# RockChip_RK3588 register map
Vendor: RockChip Electronics Co., Ltd.; Series: RK3588; File version: 0.1
Registers are 32-bit, read-write, no defined reset value unless marked. A register's access mark holds for its fields unless they carry their own. Offsets are from the block's base; [hi:lo] are bit positions; {n}, {i} and the like mark numbered series; 'fields as' and 'values as' point back to an identical list; <NAME> marks a mode.

## CRU_DSU
Base 0xFD818000
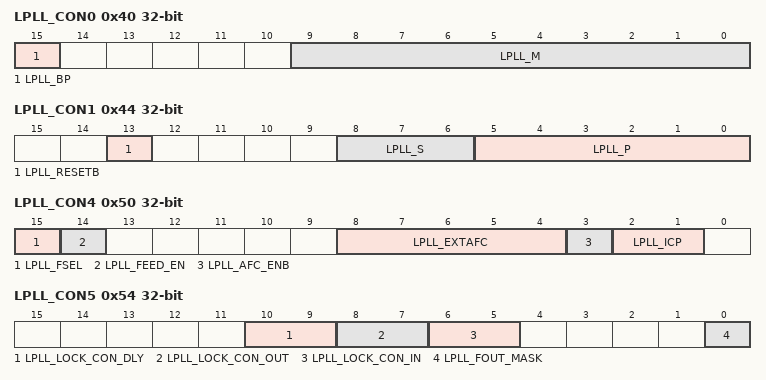
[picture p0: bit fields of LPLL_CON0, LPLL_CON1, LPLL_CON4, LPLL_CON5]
0x40 LPLL_CON0 — LPLL configuration register 0
  [15] LPLL_BP — BYPASS: Bypass mode control signal.
    1=BYPASS (bypass mode is enabled. (FOUT = FIN).); 0=NORMAL (PLL operates normally.)
  [9:0] LPLL_M — M: Division value of the 10-bit programmable main-divider. PLL has to be reset if M value is changed. 64 <= pll_m <= 1023
0x44 LPLL_CON1 — LPLL configuration register 1
  [13] LPLL_RESETB — RESETB: Power down control signal.
    0=NORMAL (RESETB=0 from 1, PLL starts its normal operation after lock time.); 1=POWER_DOWN (RESETB=1, power down mode is enabled and all digital blocks are reset.)
  [8:6] LPLL_S — Division value of the 3-bit programmable scaler. 0 <= pll_s <= 6
  [5:0] LPLL_P — P: Division value of the 6-bit programmable pre-divider. PLL has to be reset if P value is changed. 1 <= pll_p <= 63
0x50 LPLL_CON4 — LPLL configuration register 4
  [15] LPLL_FSEL — FSEL: Monitoring pin.
    0=FREF (FEED_OUT = FREF.); 1=FEED (FEED_OUT = FEED.)
  [14] LPLL_FEED_EN — FEED_EN: Monitoring pin.
    0=DISABLED (FEED_OUT is disabled.); 1=ENABLED (FEED_OUT is enabled.)
  [8:4] LPLL_EXTAFC — EXTAFC: Monitoring pin. If pll_afc_enb=1, AFC is disabled and VCO is calibrated manually by pll_extafc[4:0] for the test of VCO range.
  [3] LPLL_AFC_ENB — AFC_ENB: Monitoring pin.
    0=ENABLED (AFC is enabled and VCO is calibrated automatically.); 1=DISABLED (AFC is disabled and VCO is calibrated manually by pll_extafc[4:0] for the test of VCO range.)
  [2:1] LPLL_ICP — Charge-pump current control signal.
0x54 LPLL_CON5 — LPLL configuration register 5
  [10:9] LPLL_LOCK_CON_DLY — LOCK_CON_DLY: Lock detector setting of the detection resolution.
  [8:7] LPLL_LOCK_CON_OUT — LOCK_CON_OUT: Lock detector setting of the output margin.
  [6:5] LPLL_LOCK_CON_IN — LOCK_CON_IN: Lock detector setting of the input margin.
  [0] LPLL_FOUT_MASK — FOUT_MASK: Scaler's re-initialization time control pin.
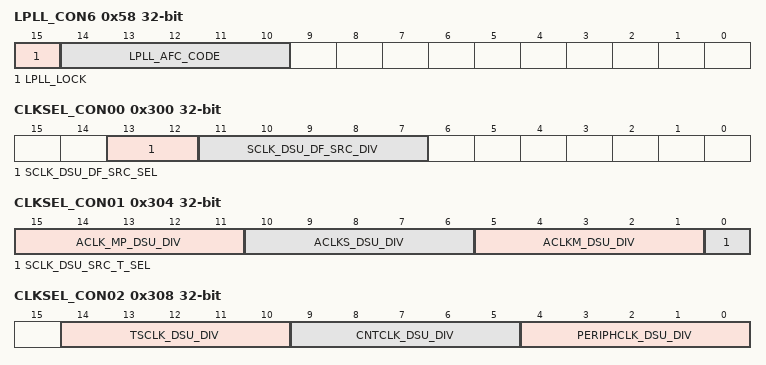
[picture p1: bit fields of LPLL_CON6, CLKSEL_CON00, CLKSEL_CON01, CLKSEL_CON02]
0x58 LPLL_CON6 — LPLL configuration register 6
  [15] LPLL_LOCK — LOCK: PLL lock flag.
    0=UNLOCKED (PLL is unlocked.); 1=LOCKED (PLL is locked.)
  [14:10] LPLL_AFC_CODE — AFC_CODE: Monitoring pin. Output code of AFC(5 bits).
0x280 MODE_CON00 — Internal PLL mode select register 0
  [1:0] CLK_LPLL_MODE — clk_lpll_mux clock mux.
    0=XIN_OSC0_FUNC; 1=CLK_LPLL; 2=CLK_DEEPSLOW
0x300 CLKSEL_CON00 — Internal clock select and division register 0
  [13:12] SCLK_DSU_DF_SRC_SEL — sclk_dsu_df_src clock mux.
    0=CLK_B0PLL_MUX; 1=CLK_B1PLL_MUX; 2=CLK_LPLL_MUX; 3=CLK_GPLL_MUX
  [11:7] SCLK_DSU_DF_SRC_DIV — Divide sclk_dsu_df_src by (div_con + 1).
0x304 CLKSEL_CON01 — Internal clock select and division register 1
  [15:11] ACLK_MP_DSU_DIV — Divide aclk_mp_dsu by (div_con + 1).
  [10:6] ACLKS_DSU_DIV — Divide aclks_dsu by (div_con + 1).
  [5:1] ACLKM_DSU_DIV — Divide aclkm_dsu by (div_con + 1).
  [0] SCLK_DSU_SRC_T_SEL — sclk_dsu_src_t clock mux.
    0=SCLK_DSU_SRC; 1=CLK_DSU_PVTPLL_T
0x308 CLKSEL_CON02 — Internal clock select and division register 2
  [14:10] TSCLK_DSU_DIV — Divide tsclk_dsu by (div_con + 1).
  [9:5] CNTCLK_DSU_DIV — Divide cntclk_dsu by (div_con + 1).
  [4:0] PERIPHCLK_DSU_DIV — Divide periphclk_dsu by (div_con + 1).
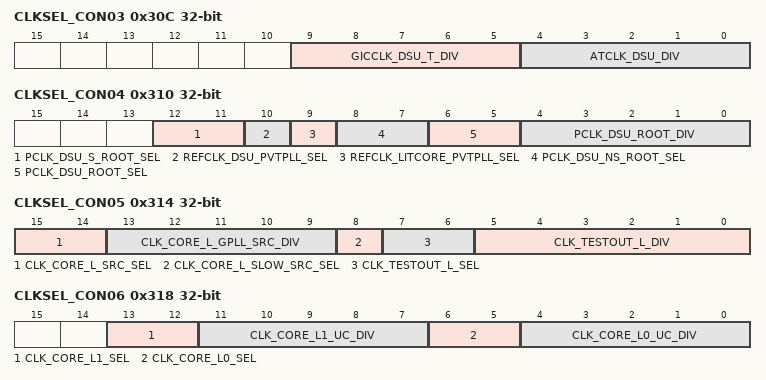
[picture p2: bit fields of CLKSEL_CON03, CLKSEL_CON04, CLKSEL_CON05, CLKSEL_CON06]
0x30C CLKSEL_CON03 — Internal clock select and division register 3
  [9:5] GICCLK_DSU_T_DIV — Divide gicclk_dsu_t by (div_con + 1).
  [4:0] ATCLK_DSU_DIV — Divide atclk_dsu by (div_con + 1).
0x310 CLKSEL_CON04 — Internal clock select and division register 4
  [12:11] PCLK_DSU_S_ROOT_SEL — pclk_dsu_s_root clock mux.
    0=CLK_MATRIX_100M_SRC; 1=CLK_MATRIX_50M_SRC; 2=XIN_OSC0_FUNC
  [10] REFCLK_DSU_PVTPLL_SEL — refclk_dsu_pvtpll clock mux.
    0=SCLK_DSU_SRC; 1=XIN_OSC0_FUNC
  [9] REFCLK_LITCORE_PVTPLL_SEL — refclk_litcore_pvtpll clock mux.
    0=CLK_CORE_L; 1=XIN_OSC0_FUNC
  [8:7] PCLK_DSU_NS_ROOT_SEL — pclk_dsu_ns_root clock mux.
    0=CLK_MATRIX_100M_SRC; 1=CLK_MATRIX_50M_SRC; 2=XIN_OSC0_FUNC
  [6:5] PCLK_DSU_ROOT_SEL — pclk_dsu_root clock mux.
    values as CLKSEL_CON00.SCLK_DSU_DF_SRC_SEL
  [4:0] PCLK_DSU_ROOT_DIV — Divide pclk_dsu_root by (div_con + 1).
0x314 CLKSEL_CON05 — Internal clock select and division register 5
  [15:14] CLK_CORE_L_SRC_SEL — clk_core_l_src clock mux.
    0=CLK_CORE_L_SLOW_SRC; 1=CLK_CORE_L_GPLL_SRC; 2=CLK_LPLL
  [13:9] CLK_CORE_L_GPLL_SRC_DIV — Divide clk_core_l_gpll_src by (div_con + 1).
  [8] CLK_CORE_L_SLOW_SRC_SEL — clk_core_l_slow_src clock mux.
    0=XIN_OSC0_FUNC; 1=CLK_DEEPSLOW
  [7:6] CLK_TESTOUT_L_SEL — clk_testout_l clock mux.
    0=CLK_LPLL; 1=CLK_CORE_L_PVTPLL; 2=SCLK_DSU_SRC; 3=CLK_DSU_PVTPLL
  [5:0] CLK_TESTOUT_L_DIV — Divide clk_testout_l by (div_con + 1).
0x318 CLKSEL_CON06 — Internal clock select and division register 6
  [13:12] CLK_CORE_L1_SEL — clk_core_l1 clock mux.
    0=CLK_CORE_L1_UC; 1=CLK_CORE_L1_CLEAN; 2=CLK_CORE_L_PVTPLL_T
  [11:7] CLK_CORE_L1_UC_DIV — Divide clk_core_l1_uc by (div_con + 1).
  [6:5] CLK_CORE_L0_SEL — clk_core_l0 clock mux.
    0=CLK_CORE_L0_UC; 1=CLK_CORE_L0_CLEAN; 2=CLK_CORE_L_PVTPLL_T
  [4:0] CLK_CORE_L0_UC_DIV — Divide clk_core_l0_uc by (div_con + 1).
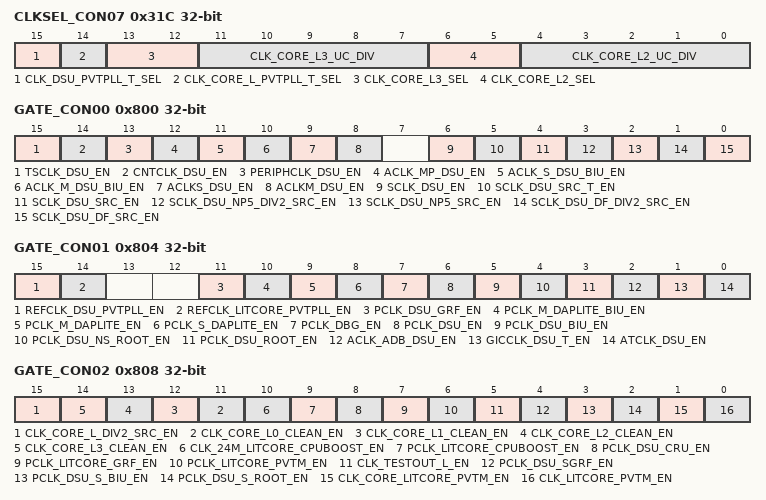
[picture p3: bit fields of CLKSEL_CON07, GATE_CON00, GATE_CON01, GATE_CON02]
0x31C CLKSEL_CON07 — Internal clock select and division register 7
  [15] CLK_DSU_PVTPLL_T_SEL — clk_dsu_pvtpll_t clock mux.
    0=CLK_DEEPSLOW; 1=CLK_DSU_PVTPLL
  [14] CLK_CORE_L_PVTPLL_T_SEL — clk_core_l_pvtpll_t clock mux.
    0=CLK_DEEPSLOW; 1=CLK_CORE_L_PVTPLL
  [13:12] CLK_CORE_L3_SEL — clk_core_l3 clock mux.
    0=CLK_CORE_L3_UC; 1=CLK_CORE_L3_CLEAN; 2=CLK_CORE_L_PVTPLL_T
  [11:7] CLK_CORE_L3_UC_DIV — Divide clk_core_l3_uc by (div_con + 1).
  [6:5] CLK_CORE_L2_SEL — clk_core_l2 clock mux.
    0=CLK_CORE_L2_UC; 1=CLK_CORE_L2_CLEAN; 2=CLK_CORE_L_PVTPLL_T
  [4:0] CLK_CORE_L2_UC_DIV — Divide clk_core_l2_uc by (div_con + 1).
0x800 GATE_CON00 — Internal clock gate and division register 0
  [all] fields
    0=ENABLE; 1=DISABLE
  [15] TSCLK_DSU_EN — tsclk_dsu clock gating control.
  [14] CNTCLK_DSU_EN — cntclk_dsu clock gating control.
  [13] PERIPHCLK_DSU_EN — periphclk_dsu clock gating control.
  [12] ACLK_MP_DSU_EN — aclk_mp_dsu clock gating control.
  [11] ACLK_S_DSU_BIU_EN — aclk_s_dsu_biu clock gating control.
  [10] ACLK_M_DSU_BIU_EN — aclk_m_dsu_biu clock gating control.
  [9] ACLKS_DSU_EN — aclks_dsu clock gating control.
  [8] ACLKM_DSU_EN — aclkm_dsu clock gating control.
  [6] SCLK_DSU_EN — sclk_dsu clock gating control.
  [5] SCLK_DSU_SRC_T_EN — sclk_dsu_src_t clock gating control.
  [4] SCLK_DSU_SRC_EN — sclk_dsu_src clock gating control.
  [3] SCLK_DSU_NP5_DIV2_SRC_EN — sclk_dsu_np5_div2_src clock gating control.
  [2] SCLK_DSU_NP5_SRC_EN — sclk_dsu_np5_src clock gating control.
  [1] SCLK_DSU_DF_DIV2_SRC_EN — sclk_dsu_df_div2_src clock gating control.
  [0] SCLK_DSU_DF_SRC_EN — sclk_dsu_df_src clock gating control.
0x804 GATE_CON01 — Internal clock gate and division register 1
  [all] fields
    0=ENABLE; 1=DISABLE
  [15] REFCLK_DSU_PVTPLL_EN — refclk_dsu_pvtpll clock gating control.
  [14] REFCLK_LITCORE_PVTPLL_EN — refclk_litcore_pvtpll clock gating control.
  [11] PCLK_DSU_GRF_EN — pclk_dsu_grf clock gating control.
  [10] PCLK_M_DAPLITE_BIU_EN — pclk_m_daplite_biu clock gating control.
  [9] PCLK_M_DAPLITE_EN — pclk_m_daplite clock gating control.
  [8] PCLK_S_DAPLITE_EN — pclk_s_daplite clock gating control.
  [7] PCLK_DBG_EN — pclk_dbg clock gating control.
  [6] PCLK_DSU_EN — pclk_dsu clock gating control.
  [5] PCLK_DSU_BIU_EN — pclk_dsu_biu clock gating control.
  [4] PCLK_DSU_NS_ROOT_EN — pclk_dsu_ns_root clock gating control.
  [3] PCLK_DSU_ROOT_EN — pclk_dsu_root clock gating control.
  [2] ACLK_ADB_DSU_EN — aclk_adb_dsu clock gating control.
  [1] GICCLK_DSU_T_EN — gicclk_dsu_t clock gating control.
  [0] ATCLK_DSU_EN — atclk_dsu clock gating control.
0x808 GATE_CON02 — Internal clock gate and division register 2
  [all] fields
    0=ENABLE; 1=DISABLE
  [15] CLK_CORE_L_DIV2_SRC_EN — clk_core_l_div2_src clock gating control.
  [n+11] CLK_CORE_L{n}_CLEAN_EN (n=0..3) — clk_core_l{n}_clean clock gating control.
  [10] CLK_24M_LITCORE_CPUBOOST_EN — clk_24m_litcore_cpuboost clock gating control.
  [9] PCLK_LITCORE_CPUBOOST_EN — pclk_litcore_cpuboost clock gating control.
  [8] PCLK_DSU_CRU_EN — pclk_dsu_cru clock gating control.
  [7] PCLK_LITCORE_GRF_EN — pclk_litcore_grf clock gating control.
  [6] PCLK_LITCORE_PVTM_EN — pclk_litcore_pvtm clock gating control.
  [5] CLK_TESTOUT_L_EN — clk_testout_l clock gating control.
  [4] PCLK_DSU_SGRF_EN — pclk_dsu_sgrf clock gating control.
  [3] PCLK_DSU_S_BIU_EN — pclk_dsu_s_biu clock gating control.
  [2] PCLK_DSU_S_ROOT_EN — pclk_dsu_s_root clock gating control.
  [1] CLK_CORE_LITCORE_PVTM_EN — clk_core_litcore_pvtm clock gating control.
  [0] CLK_LITCORE_PVTM_EN — clk_litcore_pvtm clock gating control.
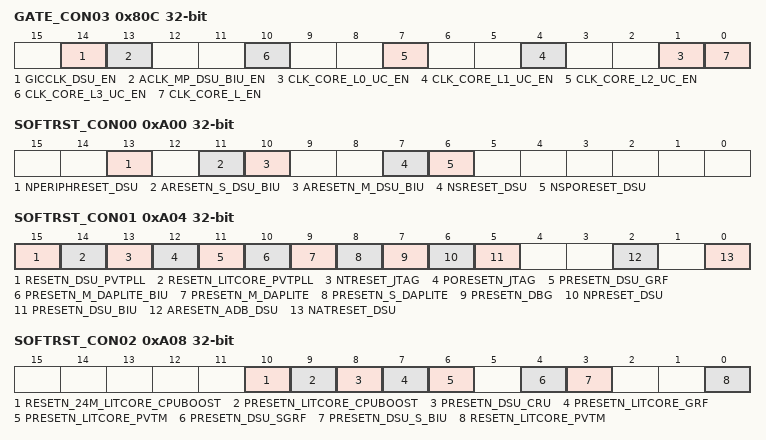
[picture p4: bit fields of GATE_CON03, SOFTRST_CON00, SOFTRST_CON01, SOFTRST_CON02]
0x80C GATE_CON03 — Internal clock gate and division register 3
  [all] fields
    0=ENABLE; 1=DISABLE
  [14] GICCLK_DSU_EN — gicclk_dsu clock gating control.
  [13] ACLK_MP_DSU_BIU_EN — aclk_mp_dsu_biu clock gating control.
  [3n+1] CLK_CORE_L{n}_UC_EN (n=0..3) — clk_core_l{n}_uc clock gating control.
  [0] CLK_CORE_L_EN — clk_core_l clock gating control.
0xA00 SOFTRST_CON00 — Internal clock reset register 0
  [13] NPERIPHRESET_DSU — When high, reset relative logic
  [11] ARESETN_S_DSU_BIU — When high, reset relative logic
  [10] ARESETN_M_DSU_BIU — When high, reset relative logic
  [7] NSRESET_DSU — When high, reset relative logic
  [6] NSPORESET_DSU — When high, reset relative logic
0xA04 SOFTRST_CON01 — Internal clock reset register 1
  [15] RESETN_DSU_PVTPLL — When high, reset relative logic
  [14] RESETN_LITCORE_PVTPLL — When high, reset relative logic
  [13] NTRESET_JTAG — When high, reset relative logic
  [12] PORESETN_JTAG — When high, reset relative logic
  [11] PRESETN_DSU_GRF — When high, reset relative logic
  [10] PRESETN_M_DAPLITE_BIU — When high, reset relative logic
  [9] PRESETN_M_DAPLITE — When high, reset relative logic
  [8] PRESETN_S_DAPLITE — When high, reset relative logic
  [7] PRESETN_DBG — When high, reset relative logic
  [6] NPRESET_DSU — When high, reset relative logic
  [5] PRESETN_DSU_BIU — When high, reset relative logic
  [2] ARESETN_ADB_DSU — When high, reset relative logic
  [0] NATRESET_DSU — When high, reset relative logic
0xA08 SOFTRST_CON02 — Internal clock reset register 2
  [10] RESETN_24M_LITCORE_CPUBOOST — When high, reset relative logic
  [9] PRESETN_LITCORE_CPUBOOST — When high, reset relative logic
  [8] PRESETN_DSU_CRU — When high, reset relative logic
  [7] PRESETN_LITCORE_GRF — When high, reset relative logic
  [6] PRESETN_LITCORE_PVTM — When high, reset relative logic
  [4] PRESETN_DSU_SGRF — When high, reset relative logic
  [3] PRESETN_DSU_S_BIU — When high, reset relative logic
  [0] RESETN_LITCORE_PVTM — When high, reset relative logic
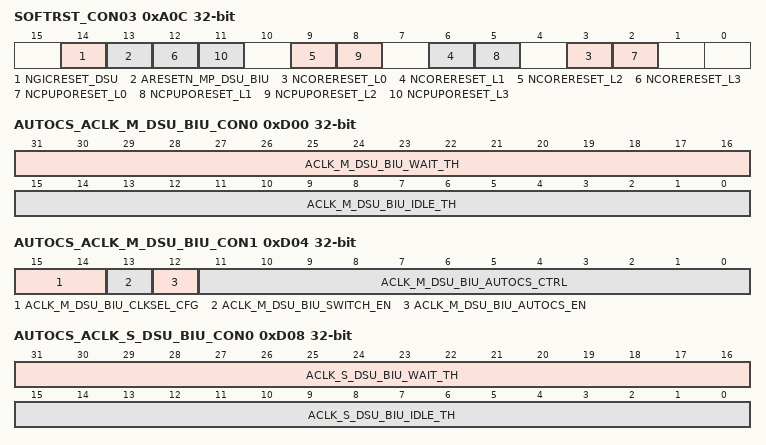
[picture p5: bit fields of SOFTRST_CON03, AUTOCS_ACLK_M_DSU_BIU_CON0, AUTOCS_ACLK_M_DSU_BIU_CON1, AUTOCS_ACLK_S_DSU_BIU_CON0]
0xA0C SOFTRST_CON03 — Internal clock reset register 3
  [14] NGICRESET_DSU — When high, reset relative logic
  [13] ARESETN_MP_DSU_BIU — When high, reset relative logic
  [3n+3] NCORERESET_L{n} (n=0..3) — When high, reset relative logic
  [3n+2] NCPUPORESET_L{n} (n=0..3) — When high, reset relative logic
0xD00 AUTOCS_ACLK_M_DSU_BIU_CON0 — Auto clock switch control register 0
  [31:16] ACLK_M_DSU_BIU_WAIT_TH — wait_th. Wait time threshold, measured by original clk.
  [15:0] ACLK_M_DSU_BIU_IDLE_TH — idle_th. Idle time threshold, measured by original clk.
0xD04 AUTOCS_ACLK_M_DSU_BIU_CON1 — Auto clock switch control register 1
  [15:14] ACLK_M_DSU_BIU_CLKSEL_CFG — clksel_cfg Auto switch clock selection.
    0=ORIGINAL_CLK; 1=XIN_OSC0_FUNC_DIV; 2=CLK_RTC_32K
  [13] ACLK_M_DSU_BIU_SWITCH_EN — switch_en
    1=ENABLE (Enable aclk_m_dsu_biu switched to lower frequency when module is inactive.); 0=DISABLE (Disable auto switch function.)
  [12] ACLK_M_DSU_BIU_AUTOCS_EN — autocs_en
    1=ENABLE (Enable aclk_m_dsu_biu switch to lower frequency.); 0=DISABLE
  [11:0] ACLK_M_DSU_BIU_AUTOCS_CTRL — autocs_ctrl. Others: Reserved.
    0xFFF=ENABLE (Enable aclk_m_dsu_biu switch to lower frequency.); 0=DISABLE
0xD08 AUTOCS_ACLK_S_DSU_BIU_CON0 — Auto clock switch control register 0
  [31:16] ACLK_S_DSU_BIU_WAIT_TH — wait_th. Wait time threshold, measured by original clk.
  [15:0] ACLK_S_DSU_BIU_IDLE_TH — idle_th. Idle time threshold, measured by original clk.
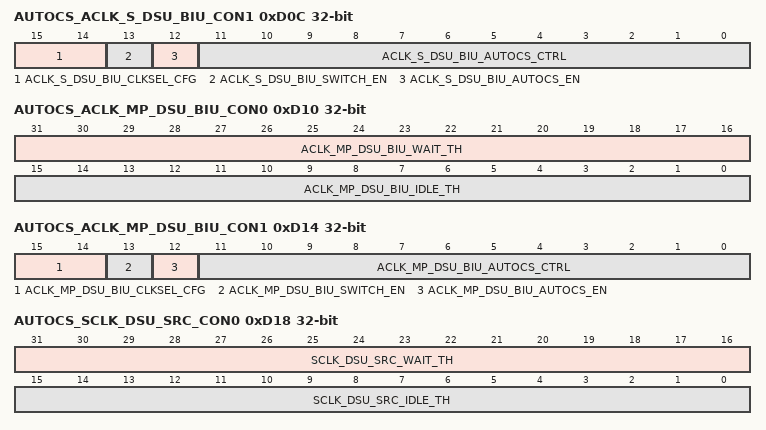
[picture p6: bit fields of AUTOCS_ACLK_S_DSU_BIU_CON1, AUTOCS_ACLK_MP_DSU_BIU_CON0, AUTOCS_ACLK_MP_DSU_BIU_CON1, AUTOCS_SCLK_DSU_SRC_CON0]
0xD0C AUTOCS_ACLK_S_DSU_BIU_CON1 — Auto clock switch control register 1
  [15:14] ACLK_S_DSU_BIU_CLKSEL_CFG — clksel_cfg Auto switch clock selection.
    0=ORIGINAL_CLK; 1=XIN_OSC0_FUNC_DIV; 2=CLK_RTC_32K
  [13] ACLK_S_DSU_BIU_SWITCH_EN — switch_en
    1=ENABLE (Enable aclk_s_dsu_biu switched to lower frequency when module is inactive.); 0=DISABLE (Disable auto switch function.)
  [12] ACLK_S_DSU_BIU_AUTOCS_EN — autocs_en
    1=ENABLE (Enable aclk_s_dsu_biu switch to lower frequency.); 0=DISABLE
  [11:0] ACLK_S_DSU_BIU_AUTOCS_CTRL — autocs_ctrl. Others: Reserved.
    0xFFF=ENABLE (Enable aclk_s_dsu_biu switch to lower frequency.); 0=DISABLE
0xD10 AUTOCS_ACLK_MP_DSU_BIU_CON0 — Auto clock switch control register 0
  [31:16] ACLK_MP_DSU_BIU_WAIT_TH — wait_th. Wait time threshold, measured by original clk.
  [15:0] ACLK_MP_DSU_BIU_IDLE_TH — idle_th. Idle time threshold, measured by original clk.
0xD14 AUTOCS_ACLK_MP_DSU_BIU_CON1 — Auto clock switch control register 1
  [15:14] ACLK_MP_DSU_BIU_CLKSEL_CFG — clksel_cfg Auto switch clock selection.
    0=ORIGINAL_CLK; 1=XIN_OSC0_FUNC_DIV; 2=CLK_RTC_32K
  [13] ACLK_MP_DSU_BIU_SWITCH_EN — switch_en
    1=ENABLE (Enable aclk_mp_dsu_biu switched to lower frequency when module is inactive.); 0=DISABLE (Disable auto switch function.)
  [12] ACLK_MP_DSU_BIU_AUTOCS_EN — autocs_en
    1=ENABLE (Enable aclk_mp_dsu_biu switch to lower frequency.); 0=DISABLE
  [11:0] ACLK_MP_DSU_BIU_AUTOCS_CTRL — autocs_ctrl. Others: Reserved.
    0xFFF=ENABLE (Enable aclk_mp_dsu_biu switch to lower frequency.); 0=DISABLE
0xD18 AUTOCS_SCLK_DSU_SRC_CON0 — Auto clock switch control register 0
  [31:16] SCLK_DSU_SRC_WAIT_TH — wait_th. Wait time threshold, measured by original clk.
  [15:0] SCLK_DSU_SRC_IDLE_TH — idle_th. Idle time threshold, measured by original clk.
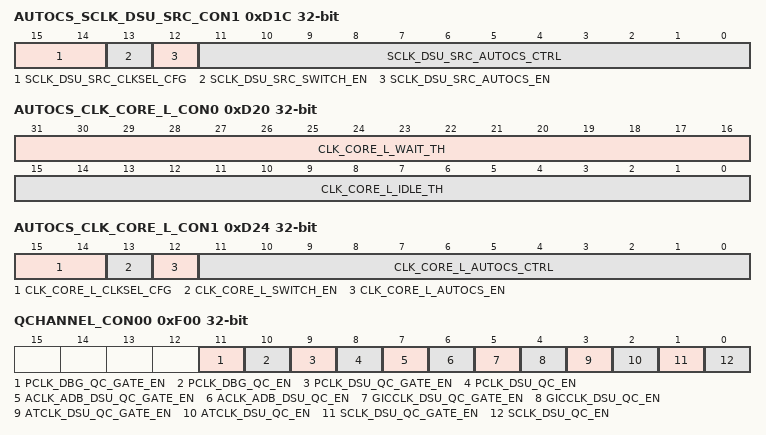
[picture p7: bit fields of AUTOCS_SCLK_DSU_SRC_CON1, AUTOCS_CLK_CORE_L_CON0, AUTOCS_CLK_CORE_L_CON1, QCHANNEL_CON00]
0xD1C AUTOCS_SCLK_DSU_SRC_CON1 — Auto clock switch control register 1
  [15:14] SCLK_DSU_SRC_CLKSEL_CFG — clksel_cfg Auto switch clock selection.
    0=ORIGINAL_CLK; 1=XIN_OSC0_FUNC_DIV; 2=CLK_RTC_32K
  [13] SCLK_DSU_SRC_SWITCH_EN — switch_en
    1=ENABLE (Enable sclk_dsu_src switched to lower frequency when module is inactive.); 0=DISABLE (Disable auto switch function.)
  [12] SCLK_DSU_SRC_AUTOCS_EN — autocs_en
    1=ENABLE (Enable sclk_dsu_src switch to lower frequency.); 0=DISABLE
  [11:0] SCLK_DSU_SRC_AUTOCS_CTRL — autocs_ctrl. Others: Reserved.
    0xFFF=ENABLE (Enable sclk_dsu_src switch to lower frequency.); 0=DISABLE
0xD20 AUTOCS_CLK_CORE_L_CON0 — Auto clock switch control register 0
  [31:16] CLK_CORE_L_WAIT_TH — wait_th. Wait time threshold, measured by original clk.
  [15:0] CLK_CORE_L_IDLE_TH — idle_th. Idle time threshold, measured by original clk.
0xD24 AUTOCS_CLK_CORE_L_CON1 — Auto clock switch control register 1
  [15:14] CLK_CORE_L_CLKSEL_CFG — clksel_cfg Auto switch clock selection.
    0=ORIGINAL_CLK; 1=XIN_OSC0_FUNC_DIV; 2=CLK_RTC_32K
  [13] CLK_CORE_L_SWITCH_EN — switch_en
    1=ENABLE (Enable clk_core_l switched to lower frequency when module is inactive.); 0=DISABLE (Disable auto switch function.)
  [12] CLK_CORE_L_AUTOCS_EN — autocs_en
    1=ENABLE (Enable clk_core_l switch to lower frequency.); 0=DISABLE
  [11:0] CLK_CORE_L_AUTOCS_CTRL — autocs_ctrl. Others: Reserved.
    0xFFF=ENABLE (Enable clk_core_l switch to lower frequency.); 0=DISABLE
0xF00 QCHANNEL_CON00 — Qchannel control register 1
  [11] PCLK_DBG_QC_GATE_EN — qc_gate_en
    1=DOC_BUG_ENABLE (Enable pclk_dbg qchannel gate function.); 0=DOC_BUG_DISABLE (Disable pclk_dbg qchannel gate function.)
  [10] PCLK_DBG_QC_EN — qc_en
    1=DOC_BUG_ENABLE (Enable pclk_dbg qchannel.); 0=DOC_BUG_DISABLE (Disable pclk_dbg qchannel.)
  [9] PCLK_DSU_QC_GATE_EN — qc_gate_en
    1=DOC_BUG_ENABLE (Enable pclk_dsu qchannel gate function.); 0=DOC_BUG_DISABLE (Disable pclk_dsu qchannel gate function.)
  [8] PCLK_DSU_QC_EN — qc_en
    1=DOC_BUG_ENABLE (Enable pclk_dsu qchannel.); 0=DOC_BUG_DISABLE (Disable pclk_dsu qchannel.)
  [7] ACLK_ADB_DSU_QC_GATE_EN — qc_gate_en
    1=DOC_BUG_ENABLE (Enable aclk_adb_dsu qchannel gate function.); 0=DOC_BUG_DISABLE (Disable aclk_adb_dsu qchannel gate function.)
  [6] ACLK_ADB_DSU_QC_EN — qc_en
    1=DOC_BUG_ENABLE (Enable aclk_adb_dsu qchannel.); 0=DOC_BUG_DISABLE (Disable aclk_adb_dsu qchannel.)
  [5] GICCLK_DSU_QC_GATE_EN — qc_gate_en
    1=DOC_BUG_ENABLE (Enable gicclk_dsu qchannel gate function.); 0=DOC_BUG_DISABLE (Disable gicclk_dsu qchannel gate function.)
  [4] GICCLK_DSU_QC_EN — qc_en
    1=DOC_BUG_ENABLE (Enable gicclk_dsu qchannel.); 0=DOC_BUG_DISABLE (Disable gicclk_dsu qchannel.)
  [3] ATCLK_DSU_QC_GATE_EN — qc_gate_en
    1=DOC_BUG_ENABLE (Enable atclk_dsu qchannel gate function.); 0=DOC_BUG_DISABLE (Disable atclk_dsu qchannel gate function.)
  [2] ATCLK_DSU_QC_EN — qc_en
    1=DOC_BUG_ENABLE (Enable atclk_dsu qchannel.); 0=DOC_BUG_DISABLE (Disable atclk_dsu qchannel.)
  [1] SCLK_DSU_QC_GATE_EN — qc_gate_en
    1=DOC_BUG_ENABLE (Enable sclk_dsu qchannel gate function.); 0=DOC_BUG_DISABLE (Disable sclk_dsu qchannel gate function.)
  [0] SCLK_DSU_QC_EN — qc_en
    1=DOC_BUG_ENABLE (Enable sclk_dsu qchannel.); 0=DOC_BUG_DISABLE (Disable sclk_dsu qchannel.)
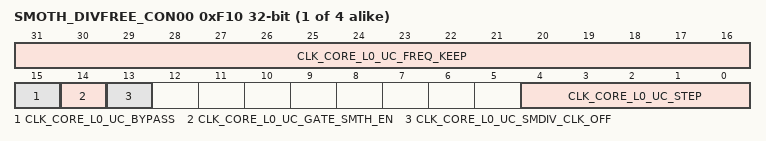
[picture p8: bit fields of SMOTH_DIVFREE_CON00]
{0xF10+4i} SMOTH_DIVFREE_CON{i:02} (i=0..3) — Smoothdiv control register
  [31:16] CLK_CORE_L{i}_UC_FREQ_KEEP — freq_keep Cycles to keep every step.
  [15] CLK_CORE_L{i}_UC_BYPASS — bypass Division signal bypass.
    1=BYPASS; 0=USE (Use Smoothdiv to control clock division.)
  [14] CLK_CORE_L{i}_UC_GATE_SMTH_EN — gate_smth_en If trigger smoothdiv function when clk been gated.
    1=ENABLE; 0=DISABLE
  [13] CLK_CORE_L{i}_UC_SMDIV_CLK_OFF — smdiv_clk_off Turn off smoothdiv module clk.
    1=OFF; 0=ON
  [4:0] CLK_CORE_L{i}_UC_STEP — step Step of div from 0x1f to setting configuration.
